# nrf9120 register map
Vendor: Nordic Semiconductor; Series: nrf91; File version: 1
CPU: CM33 r0p4, little endian, MPU, FPU, 3 interrupt priority bits, 69 interrupts
Registers are 32-bit, read-write, reset 0x0 unless marked. A register's access mark holds for its fields unless they carry their own. Offsets are from the block's base; [hi:lo] are bit positions; {n}, {i} and the like mark numbered series; 'fields as' and 'values as' point back to an identical list.

## CC_RNG_SRAM_S — CRYPTOCELL RNG SRAM interface
Base 0x50841000; alternate view of CC_AES_S
0xF00 SRAM_DATA — Read/Write data from RNG SRAM
  [31:0] SRAM_DATA — 32 bits DMA read/write from/to RNG SRAM. A 'read' or 'write' operation to this register will trigger the DMA address to be automatically incremented.
0xF04 SRAM_ADDR wo — First address given to RNG SRAM DMA for read/write transactions from/to RNG SRAM.
  [14:0] SRAM_ADDR — RNG SRAM starting address
0xF08 SRAM_DATA_READY ro reset 0x1 — RNG SRAM DMA engine is ready to read/write from/to RNG SRAM.
  [0] SRAM_READY — RNG SRAM DMA status.
    0=Busy (DMA is busy); 1=Idle (DMA is idle)

## P0_NS — GPIO Port 0
Base 0x40842500
Same registers: P0_S 0x50842500
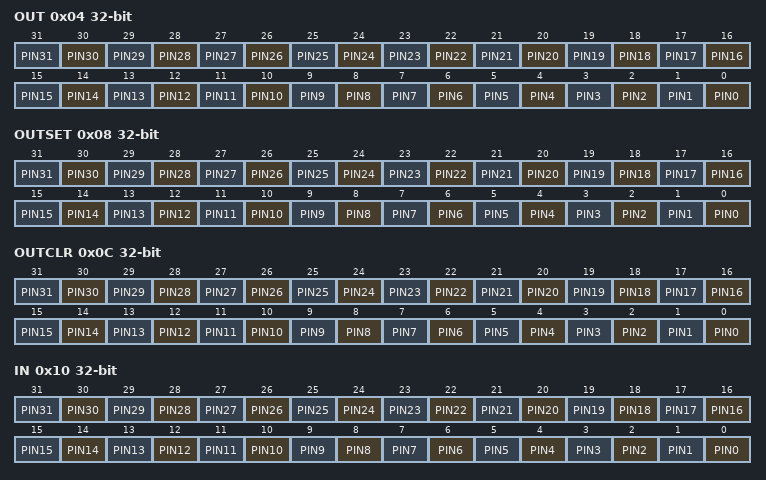
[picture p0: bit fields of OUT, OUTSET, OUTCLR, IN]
0x04 OUT — Write GPIO port
  [all] fields
    0=Low (Pin driver is low); 1=High (Pin driver is high)
  [n] PIN{n} (n=0..31)
0x08 OUTSET write-1-sets — Set individual bits in GPIO port
  [all] fields
    on read: 0=Low (Read: pin driver is low); 1=High (Read: pin driver is high) | on write: 1=Set (Write: writing a '1' sets the pin high; writing a '0' has no effect)
  [n] PIN{n} (n=0..31)
0x0C OUTCLR write-1-clears — Clear individual bits in GPIO port
  [all] fields
    on read: 0=Low (Read: pin driver is low); 1=High (Read: pin driver is high) | on write: 1=Clear (Write: writing a '1' sets the pin low; writing a '0' has no effect)
  [n] PIN{n} (n=0..31)
0x10 IN ro — Read GPIO port
  [all] fields
    0=Low (Pin input is low); 1=High (Pin input is high)
  [n] PIN{n} (n=0..31)
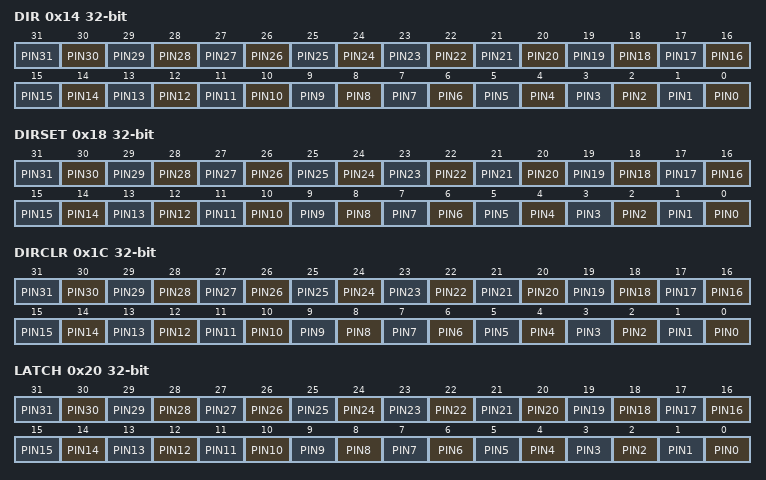
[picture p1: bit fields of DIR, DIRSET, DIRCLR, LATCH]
0x14 DIR — Direction of GPIO pins
  [all] fields
    0=Input (Pin set as input); 1=Output (Pin set as output)
  [n] PIN{n} (n=0..31)
0x18 DIRSET write-1-sets
  [all] fields
    on read: 0=Input (Read: pin set as input); 1=Output (Read: pin set as output) | on write: 1=Set (Write: writing a '1' sets pin to output; writing a '0' has no effect)
  [n] PIN{n} (n=0..31) — Set as output pin {n}
0x1C DIRCLR write-1-clears — DIR clear register
  [all] fields
    on read: 0=Input (Read: pin set as input); 1=Output (Read: pin set as output) | on write: 1=Clear (Write: writing a '1' sets pin to input; writing a '0' has no effect)
  [n] PIN{n} (n=0..31) — Set as input pin {n}
0x20 LATCH — Latch register indicating what GPIO pins that have met the criteria set in the PIN_CNF[n].SENSE registers
  [all] fields
    0=NotLatched (Criteria has not been met); 1=Latched (Criteria has been met)
  [n] PIN{n} (n=0..31) — Status on whether PIN[{n}] has met criteria set in PIN_CNF[{n}].SENSE register. Write '1' to clear.
0x24 DETECTMODE — Select between default DETECT signal behavior and LDETECT mode (For non-secure pin only)
  [0] DETECTMODE — Select between default DETECT signal behavior and LDETECT mode
    0=Default (DETECT directly connected to PIN DETECT signals); 1=LDETECT (Use the latched LDETECT behavior)
0x28 DETECTMODE_SEC — Select between default DETECT signal behavior and LDETECT mode (For secure pin only)
  fields as DETECTMODE
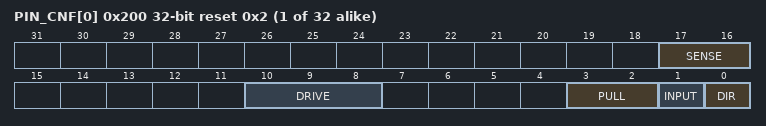
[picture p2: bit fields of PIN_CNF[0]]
{0x200+4i} PIN_CNF[{i}] (i=0..31) reset 0x2 — Description collection: Configuration of GPIO pins
  [17:16] SENSE — Pin sensing mechanism
    0=Disabled; 2=High (Sense for high level); 3=Low (Sense for low level)
  [10:8] DRIVE — Drive configuration
    0=S0S1 (Standard '0', standard '1'); 1=H0S1 (High drive '0', standard '1'); 2=S0H1 (Standard '0', high drive '1'); 3=H0H1 (High drive '0', high 'drive '1''); 4=D0S1 (Disconnect '0', standard '1' (normally used for wired-or connections)); 5=D0H1 (Disconnect '0', high drive '1' (normally used for wired-or connections)); 6=S0D1 (Standard '0', disconnect '1' (normally used for wired-and connections)); 7=H0D1 (High drive '0', disconnect '1' (normally used for wired-and connections))
  [3:2] PULL — Pull configuration
    0=Disabled (No pull); 1=Pull down on pin; 3=Pull up on pin
  [1] INPUT — Connect or disconnect input buffer
    0=Connect input buffer; 1=Disconnect input buffer
  [0] DIR — Pin direction. Same physical register as DIR register
    0=Input (Configure pin as an input pin); 1=Output (Configure pin as an output pin)
